# FM33L0XXD register map
File version: 1.0
CPU: SC000 r1p0, little endian, no MPU, FPU, 8 interrupt priority bits
Registers are 32-bit, read-write, reset 0x0 unless marked. A register's access mark holds for its fields unless they carry their own. Offsets are from the block's base; [hi:lo] are bit positions.

## RTC — RTC module information
Base 0x40011000
0x00 RTCWE
  [0] RTCWE — RTCWE field description
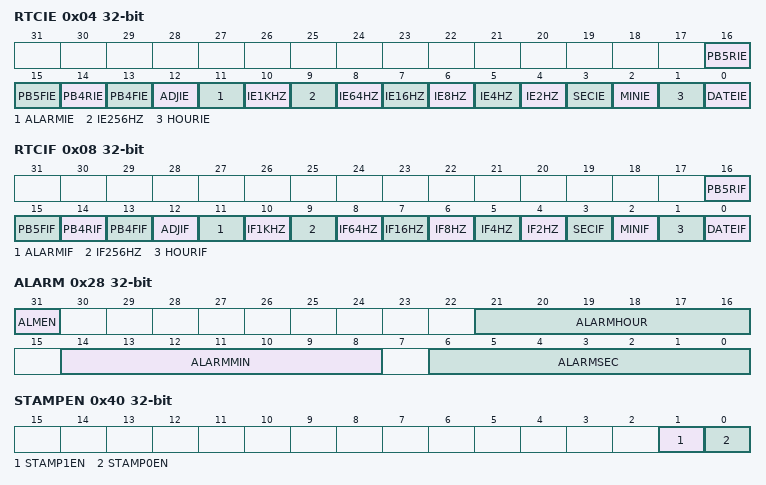
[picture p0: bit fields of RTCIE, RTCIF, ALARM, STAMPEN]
0x04 RTCIE
  [16] PB5RIE — PB5R_IE field description
  [15] PB5FIE — PB5F_IE field description
  [14] PB4RIE — PB4R_IE field description
  [13] PB4FIE — PB4F_IE field description
  [12] ADJIE — ADJ_IE field description
  [11] ALARMIE — ALARM_IE field description
  [10] IE1KHZ — IE_1KHZ field description
  [9] IE256HZ — IE_256HZ field description
  [8] IE64HZ — IE_64HZ field description
  [7] IE16HZ — IE_16HZ field description
  [6] IE8HZ — IE_8HZ field description
  [5] IE4HZ — IE_4HZ field description
  [4] IE2HZ — IE_2HZ field description
  [3] SECIE — SEC_IE field description
  [2] MINIE — MIN_IE field description
  [1] HOURIE — HOUR_IE field description
  [0] DATEIE — DATE_IE field description
0x08 RTCIF
  [16] PB5RIF — PB5R_IF field description
  [15] PB5FIF — PB5F_IF field description
  [14] PB4RIF — PB4R_IF field description
  [13] PB4FIF — PB4F_IF field description
  [12] ADJIF — ADJ_IF field description
  [11] ALARMIF — ALARM_IF field description
  [10] IF1KHZ — IF_1KHZ field description
  [9] IF256HZ — IF_256HZ field description
  [8] IF64HZ — IF_64HZ field description
  [7] IF16HZ — IF_16HZ field description
  [6] IF8HZ — IF_8HZ field description
  [5] IF4HZ — IF_4HZ field description
  [4] IF2HZ — IF_2HZ field description
  [3] SECIF — SEC_IF field description
  [2] MINIF — MIN_IF field description
  [1] HOURIF — HOUR_IF field description
  [0] DATEIF — DATE_IF field description
0x0C BCDSEC
  [6:0] BCDSEC — BCDSEC field description
0x10 BCDMIN
  [6:0] BCDMIN — BCDMIN field description
0x14 BCDHOUR
  [5:0] BCDHOUR — BCDHOUR field description
0x18 BCDDATE
  [5:0] BCDDATE — BCDDATE field description
0x1C BCDWEEK
  [2:0] BCDWEEK — BCDWEEK field description
0x20 BCDMONTH
  [4:0] BCDMONTH — BCDMONTH field description
0x24 BCDYEAR
  [7:0] BCDYEAR — BCDYEAR field description
0x28 ALARM
  [31] ALMEN — ALMEN field description
  [21:16] ALARMHOUR — ALARMHOUR field description
  [14:8] ALARMMIN — ALARMMIN field description
  [6:0] ALARMSEC — ALARMSEC field description
0x2C FSEL
  [3:0] FSEL — FSEL field description
0x30 ADJUST
  [12:0] ADJUST — ADJUST field description
0x34 ADSIGN
  [0] ADSIGN — ADSIGN field description
0x38 PR1SEN
  [0] PR1SEN — PR1SEN field description
0x3C MSECCNT
  [7:0] MSCNT — MSCNT field description
0x40 STAMPEN
  [1] STAMP1EN — STAMP1EN field description
  [0] STAMP0EN — STAMP0EN field description
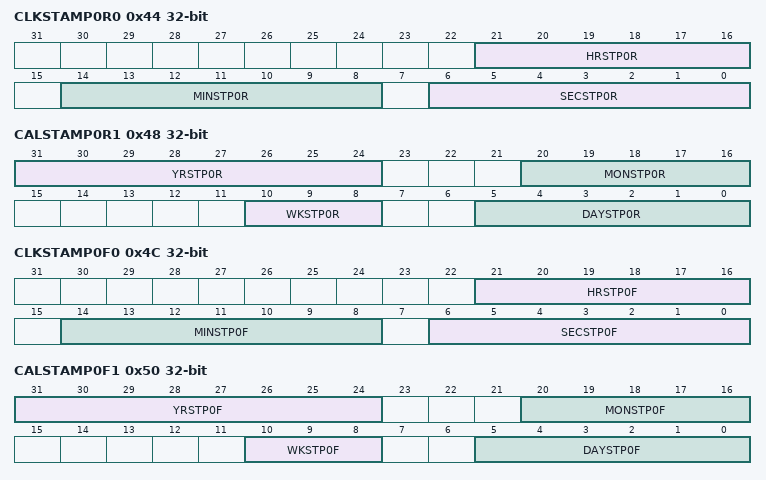
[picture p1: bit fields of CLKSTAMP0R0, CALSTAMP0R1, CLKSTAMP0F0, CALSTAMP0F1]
0x44 CLKSTAMP0R0
  [21:16] HRSTP0R — HRSTP0R field description
  [14:8] MINSTP0R — MINSTP0R field description
  [6:0] SECSTP0R — SECSTP0R field description
0x48 CALSTAMP0R1
  [31:24] YRSTP0R — YRSTP0R field description
  [20:16] MONSTP0R — MONSTP0R field description
  [10:8] WKSTP0R — WKSTP0R field description
  [5:0] DAYSTP0R — DAYSTP0R field description
0x4C CLKSTAMP0F0
  [21:16] HRSTP0F — HRSTP0F field description
  [14:8] MINSTP0F — MINSTP0F field description
  [6:0] SECSTP0F — SECSTP0F field description
0x50 CALSTAMP0F1
  [31:24] YRSTP0F — YRSTP0F field description
  [20:16] MONSTP0F — MONSTP0F field description
  [10:8] WKSTP0F — WKSTP0F field description
  [5:0] DAYSTP0F — DAYSTP0F field description
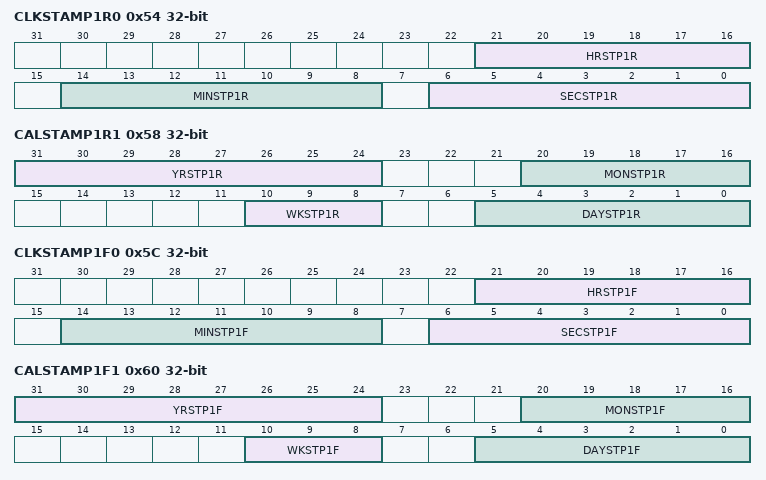
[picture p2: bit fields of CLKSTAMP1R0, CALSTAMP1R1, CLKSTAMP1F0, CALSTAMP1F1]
0x54 CLKSTAMP1R0
  [21:16] HRSTP1R — HRSTP1R field description
  [14:8] MINSTP1R — MINSTP1R field description
  [6:0] SECSTP1R — SECSTP1R field description
0x58 CALSTAMP1R1
  [31:24] YRSTP1R — YRSTP1R field description
  [20:16] MONSTP1R — MONSTP1R field description
  [10:8] WKSTP1R — WKSTP1R field description
  [5:0] DAYSTP1R — DAYSTP1R field description
0x5C CLKSTAMP1F0
  [21:16] HRSTP1F — HRSTP1F field description
  [14:8] MINSTP1F — MINSTP1F field description
  [6:0] SECSTP1F — SECSTP1F field description
0x60 CALSTAMP1F1
  [31:24] YRSTP1F — YRSTP1F field description
  [20:16] MONSTP1F — MONSTP1F field description
  [10:8] WKSTP1F — WKSTP1F field description
  [5:0] DAYSTP1F — DAYSTP1F field description
0x64 AUTOCAL
  [0] ACALEN — ACALEN field description
0x68 ADOFFSET
  [10:0] ADOFFSET — ADOFFSET field description
0x6C CALSTEP
  [0] CALSTEP — CALSTEP field description
0x70 CALBUSY
  [0] AUCALBUSY — AUCALBUSY field description
0x74 ADJCNT
  [8:0] ADJCNT — ADJCNT field description
